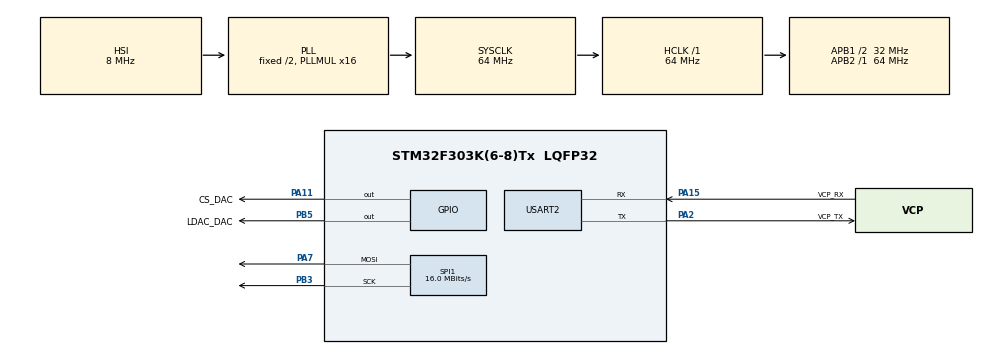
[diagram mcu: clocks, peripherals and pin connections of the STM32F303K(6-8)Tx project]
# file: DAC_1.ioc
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Mcu.Family=STM32F3
Mcu.Name=STM32F303K(6-8)Tx
Mcu.Package=LQFP32
NVIC.PriorityGroup=NVIC_PRIORITYGROUP_4
NVIC.TIM6_DAC1_IRQn=true\:0\:0\:false\:false\:true\:true\:true\:true
PA11.GPIO_Label=CS_DAC
PA11.PinState=GPIO_PIN_SET
PA11.Signal=GPIO_Output
PA13.GPIO_Label=SWDIO
PA13.Mode=Serial_Wire
PA13.Signal=SYS_JTMS-SWDIO
PA14.GPIO_Label=SWCLK
PA14.Mode=Serial_Wire
PA14.Signal=SYS_JTCK-SWCLK
PA15.GPIO_Label=VCP_RX
PA15.Mode=Asynchronous
PA15.Signal=USART2_RX
PA2.GPIO_Label=VCP_TX
PA2.Mode=Asynchronous
PA2.Signal=USART2_TX
PA7.Mode=TX_Only_Simplex_Unidirect_Master
PA7.Signal=SPI1_MOSI
PB3.Mode=TX_Only_Simplex_Unidirect_Master
PB3.Signal=SPI1_SCK
PB5.GPIO_Label=LDAC_DAC
PB5.PinState=GPIO_PIN_SET
PB5.Signal=GPIO_Output
PF0\ /\ OSC_IN.GPIO_Label=MCO
PF0\ /\ OSC_IN.Mode=HSE-External-Clock-Source
PF0\ /\ OSC_IN.Signal=RCC_OSC_IN
ProjectManager.HeapSize=0x200
ProjectManager.StackSize=0x400
ProjectManager.TargetToolchain=STM32CubeIDE
RCC.AHBFreq_Value=64000000
RCC.APB1CLKDivider=RCC_HCLK_DIV2
RCC.APB1Freq_Value=32000000
RCC.APB1TimFreq_Value=64000000
RCC.APB2Freq_Value=64000000
RCC.APB2TimFreq_Value=64000000
RCC.CortexFreq_Value=64000000
RCC.HCLKFreq_Value=64000000
RCC.HSE_VALUE=8000000
RCC.HSI_VALUE=8000000
RCC.PLLMUL=RCC_PLL_MUL16
RCC.SYSCLKFreq_VALUE=64000000
RCC.SYSCLKSourceVirtual=RCC_SYSCLKSOURCE_PLLCLK
SPI1.BaudRatePrescaler=SPI_BAUDRATEPRESCALER_4
SPI1.CalculateBaudRate=16.0 MBits/s
SPI1.DataSize=SPI_DATASIZE_16BIT
SPI1.Direction=SPI_DIRECTION_2LINES
SPI1.Mode=SPI_MODE_MASTER
SPI1.VirtualType=VM_MASTER
TIM6.Prescaler=0
USART2.VirtualMode-Asynchronous=VM_ASYNC
VP_TIM6_VS_ClockSourceINT.Mode=Enable_Timer
board=NUCLEO-F303K8

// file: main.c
/* USER CODE BEGIN Header */
/**
  ******************************************************************************
  * @file           : main.c
  * @brief          : Main program body
  ******************************************************************************
  * @attention
  *
  * Copyright (c) 2025 STMicroelectronics.
  * All rights reserved.
  *
  * This software is licensed under terms that can be found in the LICENSE file
  * in the root directory of this software component.
  * If no LICENSE file comes with this software, it is provided AS-IS.
  *
  ******************************************************************************
  */
/* USER CODE END Header */
#include "main.h"

/* USER CODE BEGIN Includes */
#include "MCP4922.h"
/* USER CODE END Includes */

SPI_HandleTypeDef hspi1;

TIM_HandleTypeDef htim6;

UART_HandleTypeDef huart2;

void SystemClock_Config(void);
static void MX_GPIO_Init(void);
static void MX_USART2_UART_Init(void);
static void MX_SPI1_Init(void);
static void MX_TIM6_Init(void);

int main(void)
{

  /* MCU Configuration--------------------------------------------------------*/

  /* Reset of all peripherals, Initializes the Flash interface and the Systick. */
  HAL_Init();

  /* Configure the system clock */
  SystemClock_Config();

  /* Initialize all configured peripherals */
  MX_GPIO_Init();
  MX_USART2_UART_Init();
  MX_SPI1_Init();
  MX_TIM6_Init();
  /* USER CODE BEGIN 2 */
  MCP4922_Init(&hspi1, &htim6);
  MCP4922_Write(DAC_CHANNEL_B, 0);
  Set_Sine_Wave(500.0f, 4095);
  //Set_Triangle_Wave(500.0f, 4095);
  /* USER CODE END 2 */

  /* Infinite loop */
  while (1)
  {

  }
}

void SystemClock_Config(void)
{
  RCC_OscInitTypeDef RCC_OscInitStruct = {0};
  RCC_ClkInitTypeDef RCC_ClkInitStruct = {0};

  /** Initializes the RCC Oscillators according to the specified parameters
  * in the RCC_OscInitTypeDef structure.
  */
  RCC_OscInitStruct.OscillatorType = RCC_OSCILLATORTYPE_HSI;
  RCC_OscInitStruct.HSIState = RCC_HSI_ON;
  RCC_OscInitStruct.HSICalibrationValue = RCC_HSICALIBRATION_DEFAULT;
  RCC_OscInitStruct.PLL.PLLState = RCC_PLL_ON;
  RCC_OscInitStruct.PLL.PLLSource = RCC_PLLSOURCE_HSI;
  RCC_OscInitStruct.PLL.PLLMUL = RCC_PLL_MUL16;
  if (HAL_RCC_OscConfig(&RCC_OscInitStruct) != HAL_OK)
  {
    Error_Handler();
  }

  /** Initializes the CPU, AHB and APB buses clocks
  */
  RCC_ClkInitStruct.ClockType = RCC_CLOCKTYPE_HCLK|RCC_CLOCKTYPE_SYSCLK
                              |RCC_CLOCKTYPE_PCLK1|RCC_CLOCKTYPE_PCLK2;
  RCC_ClkInitStruct.SYSCLKSource = RCC_SYSCLKSOURCE_PLLCLK;
  RCC_ClkInitStruct.AHBCLKDivider = RCC_SYSCLK_DIV1;
  RCC_ClkInitStruct.APB1CLKDivider = RCC_HCLK_DIV2;
  RCC_ClkInitStruct.APB2CLKDivider = RCC_HCLK_DIV1;

  if (HAL_RCC_ClockConfig(&RCC_ClkInitStruct, FLASH_LATENCY_2) != HAL_OK)
  {
    Error_Handler();
  }
}

static void MX_SPI1_Init(void)
{

  /* SPI1 parameter configuration*/
  hspi1.Instance = SPI1;
  hspi1.Init.Mode = SPI_MODE_MASTER;
  hspi1.Init.Direction = SPI_DIRECTION_2LINES;
  hspi1.Init.DataSize = SPI_DATASIZE_16BIT;
  hspi1.Init.CLKPolarity = SPI_POLARITY_LOW;
  hspi1.Init.CLKPhase = SPI_PHASE_1EDGE;
  hspi1.Init.NSS = SPI_NSS_SOFT;
  hspi1.Init.BaudRatePrescaler = SPI_BAUDRATEPRESCALER_4;
  hspi1.Init.FirstBit = SPI_FIRSTBIT_MSB;
  hspi1.Init.TIMode = SPI_TIMODE_DISABLE;
  hspi1.Init.CRCCalculation = SPI_CRCCALCULATION_DISABLE;
  hspi1.Init.CRCPolynomial = 7;
  hspi1.Init.CRCLength = SPI_CRC_LENGTH_DATASIZE;
  hspi1.Init.NSSPMode = SPI_NSS_PULSE_ENABLE;
  if (HAL_SPI_Init(&hspi1) != HAL_OK)
  {
    Error_Handler();
  }

}

static void MX_TIM6_Init(void)
{

  TIM_MasterConfigTypeDef sMasterConfig = {0};

  htim6.Instance = TIM6;
  htim6.Init.Prescaler = 0;
  htim6.Init.CounterMode = TIM_COUNTERMODE_UP;
  htim6.Init.Period = 65535;
  htim6.Init.AutoReloadPreload = TIM_AUTORELOAD_PRELOAD_DISABLE;
  if (HAL_TIM_Base_Init(&htim6) != HAL_OK)
  {
    Error_Handler();
  }
  sMasterConfig.MasterOutputTrigger = TIM_TRGO_RESET;
  sMasterConfig.MasterSlaveMode = TIM_MASTERSLAVEMODE_DISABLE;
  if (HAL_TIMEx_MasterConfigSynchronization(&htim6, &sMasterConfig) != HAL_OK)
  {
    Error_Handler();
  }

}

static void MX_USART2_UART_Init(void)
{

  huart2.Instance = USART2;
  huart2.Init.BaudRate = 38400;
  huart2.Init.WordLength = UART_WORDLENGTH_8B;
  huart2.Init.StopBits = UART_STOPBITS_1;
  huart2.Init.Parity = UART_PARITY_NONE;
  huart2.Init.Mode = UART_MODE_TX_RX;
  huart2.Init.HwFlowCtl = UART_HWCONTROL_NONE;
  huart2.Init.OverSampling = UART_OVERSAMPLING_16;
  huart2.Init.OneBitSampling = UART_ONE_BIT_SAMPLE_DISABLE;
  huart2.AdvancedInit.AdvFeatureInit = UART_ADVFEATURE_NO_INIT;
  if (HAL_UART_Init(&huart2) != HAL_OK)
  {
    Error_Handler();
  }

}

static void MX_GPIO_Init(void)
{
  GPIO_InitTypeDef GPIO_InitStruct = {0};

  /* GPIO Ports Clock Enable */
  __HAL_RCC_GPIOF_CLK_ENABLE();
  __HAL_RCC_GPIOA_CLK_ENABLE();
  __HAL_RCC_GPIOB_CLK_ENABLE();

  /*Configure GPIO pin Output Level */
  HAL_GPIO_WritePin(CS_DAC_GPIO_Port, CS_DAC_Pin, GPIO_PIN_SET);

  /*Configure GPIO pin Output Level */
  HAL_GPIO_WritePin(LDAC_DAC_GPIO_Port, LDAC_DAC_Pin, GPIO_PIN_SET);

  /*Configure GPIO pin : CS_DAC_Pin */
  GPIO_InitStruct.Pin = CS_DAC_Pin;
  GPIO_InitStruct.Mode = GPIO_MODE_OUTPUT_PP;
  GPIO_InitStruct.Pull = GPIO_NOPULL;
  GPIO_InitStruct.Speed = GPIO_SPEED_FREQ_LOW;
  HAL_GPIO_Init(CS_DAC_GPIO_Port, &GPIO_InitStruct);

  /*Configure GPIO pin : LDAC_DAC_Pin */
  GPIO_InitStruct.Pin = LDAC_DAC_Pin;
  GPIO_InitStruct.Mode = GPIO_MODE_OUTPUT_PP;
  GPIO_InitStruct.Pull = GPIO_NOPULL;
  GPIO_InitStruct.Speed = GPIO_SPEED_FREQ_LOW;
  HAL_GPIO_Init(LDAC_DAC_GPIO_Port, &GPIO_InitStruct);

}

/* USER CODE BEGIN 4 */
void HAL_TIM_PeriodElapsedCallback(TIM_HandleTypeDef *htim)
{
	if (htim->Instance == TIM6) {
		MCP4922_TIM_Callback();
	}
}

/* USER CODE END 4 */

void Error_Handler(void)
{
  __disable_irq();
  while (1)
  {
  }
}
